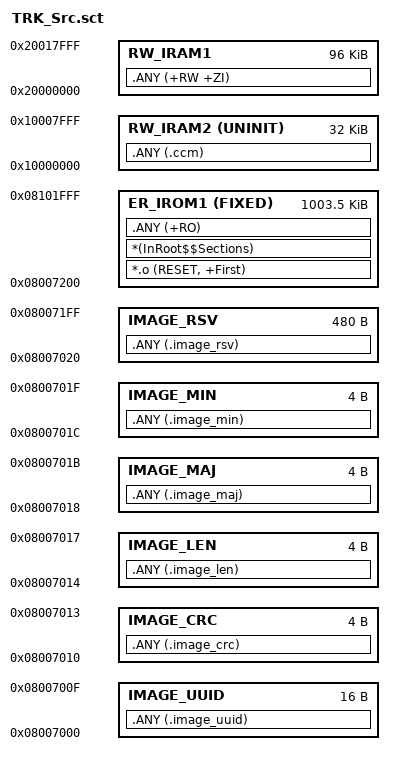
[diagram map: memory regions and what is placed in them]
; *************************************************************
; *** Scatter-Loading Description File generated by uVision ***
; *************************************************************

LR_IROM1 0x08007000 0x000FB000  {    ; load region size_region
  IMAGE_UUID 0x08007000 0x10      {
   .ANY (.image_uuid)
  }
  IMAGE_CRC 0x08007010 0x4      {
   .ANY (.image_crc)
  }
  IMAGE_LEN 0x08007014 0x4      {
   .ANY (.image_len)
  }
  IMAGE_MAJ 0x08007018 0x4      {
   .ANY (.image_maj)
  }
  IMAGE_MIN 0x0800701C 0x4      {
   .ANY (.image_min)
  }
  IMAGE_RSV 0x08007020 0x1E0      {
   .ANY (.image_rsv)
  }
  ER_IROM1 0x08007200 FIXED 0x000FAE00  {  ; load address = execution address
   *.o (RESET, +First)
   *(InRoot$$Sections)
   .ANY (+RO)
  }
  RW_IRAM1 0x20000000 0x00018000  {  ; RW data
   .ANY (+RW +ZI)
  }
  RW_IRAM2 0x10000000 UNINIT 0x00008000  {
   .ANY (.ccm)
  }
}
